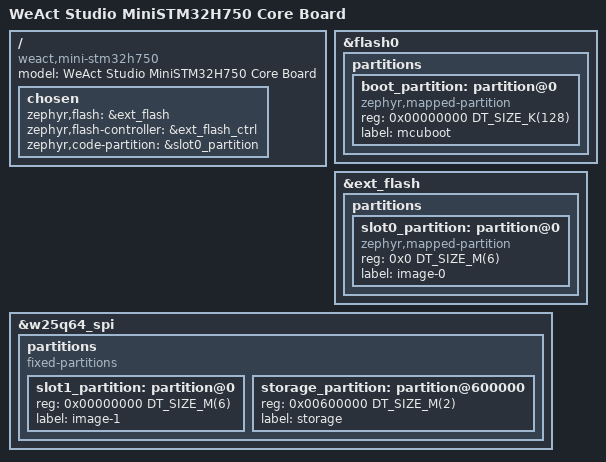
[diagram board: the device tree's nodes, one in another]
/*
 * SPDX-FileCopyrightText: Copyright The Zephyr Project Contributors
 *
 * SPDX-License-Identifier: Apache-2.0
 */

/dts-v1/;
#include "mini_stm32h750-common.dtsi"

/ {
	compatible = "weact,mini-stm32h750";
	model = "WeAct Studio MiniSTM32H750 Core Board";

	chosen {
		zephyr,flash = &ext_flash;
		zephyr,flash-controller = &ext_flash_ctrl;
		zephyr,code-partition = &slot0_partition;
	};
};

&flash0 {
	partitions {
		ranges;
		#address-cells = <1>;
		#size-cells = <1>;

		boot_partition: partition@0 {
			compatible = "zephyr,mapped-partition";
			reg = <0x00000000 DT_SIZE_K(128)>;
			label = "mcuboot";
		};
	};
};

&ext_flash {
	status = "okay";

	partitions {
		ranges;
		#address-cells = <1>;
		#size-cells = <1>;

		slot0_partition: partition@0 {
			compatible = "zephyr,mapped-partition";
			reg = <0x0 DT_SIZE_M(6)>;
			label = "image-0";
		};
	};
};

&w25q64_spi {
	partitions {
		compatible = "fixed-partitions";
		#address-cells = <1>;
		#size-cells = <1>;

		/*
		 * The secondary slot is placed on the SPI NOR flash because the
		 * application runs in place (XIP) from the QSPI flash. While the
		 * QSPI is in memory-mapped mode it cannot be written to, so the
		 * update image cannot be staged on the same QSPI device.
		 */
		slot1_partition: partition@0 {
			reg = <0x00000000 DT_SIZE_M(6)>;
			label = "image-1";
		};

		storage_partition: partition@600000 {
			reg = <0x00600000 DT_SIZE_M(2)>;
			label = "storage";
		};
	};
};
